# NUC400_v1 register map
File version: 1.0
Registers are 32-bit, read-write, reset 0x0 unless marked. A register's access mark holds for its fields unless they carry their own. Offsets are from the block's base; [hi:lo] are bit positions; {n}, {i} and the like mark numbered series; 'fields as' and 'values as' point back to an identical list.

## EADC — EADC Register Map
Base 0x40044000
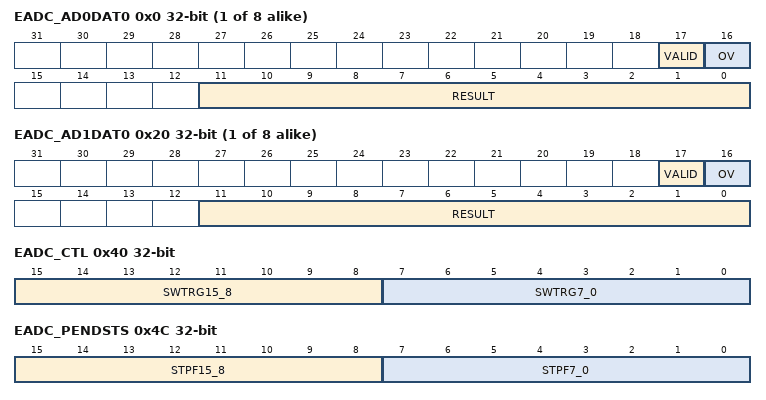
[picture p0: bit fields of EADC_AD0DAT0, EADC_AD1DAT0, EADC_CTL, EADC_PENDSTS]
{0x0+4i} EADC_AD0DAT{i} ro (i=0..7) — A/D Data Register {i} for SAMPLE{i:02}
  [17] VALID — Valid Flag
    0=Data in RESULT (EADC_ADnDATx[11:0]) is not valid; 1=Data in RESULT (EADC_ADnDATx[11:0]) is valid
  [16] OV — Overrun Flag
    0=Data in RESULT (EADC_ADnDATx[11:0]) is recent conversion result; 1=Data in RESULT (EADC_ADnDATx[11:0]) is overwrite
  [11:0] RESULT — A/D Conversion Result. This field contains 12 bits conversion result.
{0x20+4i} EADC_AD1DAT{i} ro (i=0..7) — A/D Data Register {i+8} for SAMPLE{i+10}
  fields as EADC_AD0DAT0
0x40 EADC_CTL — A/D Control Register
  [15:8] SWTRG15_8 — A/D SAMPLE17~SAMPLE10 Software Force To Start ADC Conversion
    0=No effect; 1=Start an ADC conversion when the priority is given to SAMPLE1x
  [7:0] SWTRG7_0 — A/D SAMPLE07~SAMPLE00 Software Force To Start ADC Conversion
    0=No effect; 1=Start an ADC conversion when the priority is given to SAMPLE0x
0x48 EADC_SWTRG wo — A/D SAMPLE Module Software Start Register
0x4C EADC_PENDSTS ro — A/D Start of Conversion Pending Flag Register
  [15:8] STPF15_8 — A/D SAMPLE17~SAMPLE10 Start Of Conversion Pending Flag
    0=There is no pending conversion for SAMPLE1x; 1=SAMPLE1x ADC start of conversion is pending
  [7:0] STPF7_0 — A/D SAMPLE07~SAMPLE00 Start Of Conversion Pending Flag
    0=There is no pending conversion for SAMPLE0x; 1=SAMPLE0x ADC start of conversion is pending
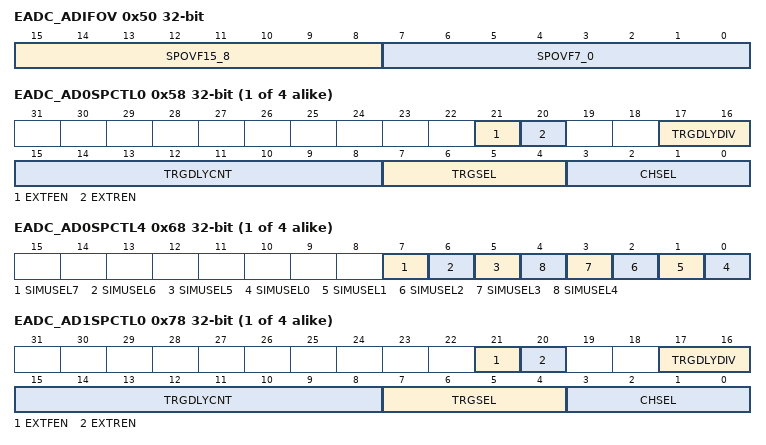
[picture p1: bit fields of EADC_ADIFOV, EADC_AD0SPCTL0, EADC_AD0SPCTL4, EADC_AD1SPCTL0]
0x50 EADC_ADIFOV — A/D ADINT3~0 Interrupt Flag Overrun Register
  [15:8] SPOVF15_8 — A/D SAMPLE17~SAMPLE10 Start Of Conversion Overrun Flag
    0=No SAMPLE1x event overrun; 1=Indicates a new SAMPLE1x event is generated while an old one event is pending
  [7:0] SPOVF7_0 — A/D SAMPLE07~SAMPLE00 Start Of Conversion Overrun Flag
    0=No SAMPLE0x event overrun; 1=Indicates a new SAMPLE0x event is generated while an old one event is pending
0x54 EADC_OVSTS — A/D SAMPLE Module Start of Conversion Overrun Flag Register
{0x58+4i} EADC_AD0SPCTL{i} (i=0..3) — A/D SAMPLE{i:02} Control Register
  [21] EXTFEN — A/D External Pin Falling Edge Trigger Enable Bit
    0=A/D external pin falling edge trigger Disabled; 1=A/D external pin falling edge trigger Enabled
  [20] EXTREN — A/D External Pin Rising Edge Trigger Enable Bit
    0=A/D external pin rising edge trigger Disabled; 1=A/D external pin rising edge trigger Enabled
  [17:16] TRGDLYDIV — A/D SAMPLE MODULE Start Of Conversion Trigger Delay Clock Divider Selection. Trigger delay clock frequency:
    0=ADC_CLK/1; 1=ADC_CLK/2; 2=ADC_CLK/4; 3=ADC_CLK/16
  [15:8] TRGDLYCNT — A/D SAMPLE MODULE Start Of Conversion Trigger Delay Time
  [7:4] TRGSEL — A/D SAMPLE MODULE Start Of Conversion Trigger Source Selection
    0=Disable hardware trigger; 1=External pin (STADC) trigger; 2=ADC ADINT0 interrupt EOC pulse trigger; 3=ADC ADINT1 interrupt EOC pulse trigger; {v}=Timer{v-4} overflow pulse trigger (v=4..7); 8=EPWM0_CH0 trigger; 9=EPWM0_CH2 trigger; 10=EPWM0_CH4 trigger; 11=EPWM1_CH0 trigger; 12=EPWM1_CH2 trigger; 13=EPWM1_CH4 trigger; 14=PWM0_CH0 trigger; 15=PWM0_CH1 trigger
  [3:0] CHSEL — A/D SAMPLE MODULE 0,1 Channel Selection
    {v}=ADCn_CH{v} (v=0..7); 8=VBG. OP1; 9=VTEMP; 10=AVSS; 11=OP0
{0x58+4i} EADC_AD0SPCTL{i} (i=4..7) — A/D SAMPLE{i:02} Control Register
  [7] SIMUSEL7 — A/D SAMPLE07, SAMPLE17 Simultaneous Sampling Mode Selection
    0=SAMPLE07, SAMPLE17 are in single sampling mode, both SAMPLE07 and SAMPLE17's 3 bits of CHSEL define the ADC channels to be converted; 1=SAMPLE07, SAMPLE17 are in simultaneous sampling mode, Only SAMPLE07 can trigger the both ADC conversions of SAMPLE07 and SAMPLE17, SAMPLE17 trigger select TRGSEL is ignored. If SAMPLE07's CHSEL = 1, SAMPLE17's CHSEL = 3, the pair of channels are ADC0_CH1, ADC1_CH3, they will do the ADC conversion at the same time to reach the simulataneous sampling goal
  [6] SIMUSEL6 — A/D SAMPLE06, SAMPLE16 Simultaneous Sampling Mode Selection
    0=SAMPLE06, SAMPLE16 are in single sampling mode, both SAMPLE06 and SAMPLE16's 3 bits of CHSEL define the ADC channels to be converted; 1=SAMPLE06, SAMPLE16 are in simultaneous sampling mode, Only SAMPLE06 can trigger the both ADC conversions of SAMPLE06 and SAMPLE16, SAMPLE16 trigger select TRGSEL is ignored. If SAMPLE06's CHSEL = 1, and SAMPLE16's CHSEL = 3, the pair of channels are ADC0_CH1, ADC1_CH3, they will do the ADC conversion at the same time to reach the simulataneous sampling goal
  [5] SIMUSEL5 — A/D SAMPLE05, SAMPLE15 Simultaneous Sampling Mode Selection
    0=SAMPLE05, SAMPLE15 are in single sampling mode, both SAMPLE05 and SAMPLE15's 3 bits of CHSEL define the ADC channels to be converted; 1=SAMPLE05, SAMPLE15 are in simultaneous sampling mode, Only SAMPLE05 can trigger the both ADC conversions of SAMPLE05 and SAMPLE15, SAMPLE15 trigger select TRGSEL is ignored. if SAMPLE05's CHSEL = 1, and SAMPLE15's CHSEL = 3, the pair of channels are ADC0_CH1, ADC1_CH3, they will do the ADC conversion at the same time to reach the simulataneous sampling goal
  [n] SIMUSEL{n} (n=0..4) — A/D SAMPLE{n:02}, SAMPLE{n+10} Simultaneous Sampling Mode Selection
    0=SAMPLE{n:02}, SAMPLE{n+10} are in single sampling mode, both SAMPLE{n:02} and SAMPLE{n+10}'s 3 bits of CHSEL define the ADC channels to be converted; 1=SAMPLE{n:02}, SAMPLE{n+10} are in simultaneous sampling mode, Only SAMPLE{n:02} can trigger the both ADC conversions of SAMPLE{n:02} and SAMPLE{n+10}, SAMPLE{n+10} trigger select TRGSEL is ignored. If SAMPLE{n:02}'s CHSEL = 1, and SAMPLE{n+10}'s CHSEL = 3, the pair of channels are ADC0_CH1, ADC1_CH3, they will do the ADC conversion at the same time to reach the simulataneous sampling goal
{0x78+4i} EADC_AD1SPCTL{i} (i=0..3) — A/D SAMPLE{i+10} Control Register
  fields as EADC_AD0SPCTL0
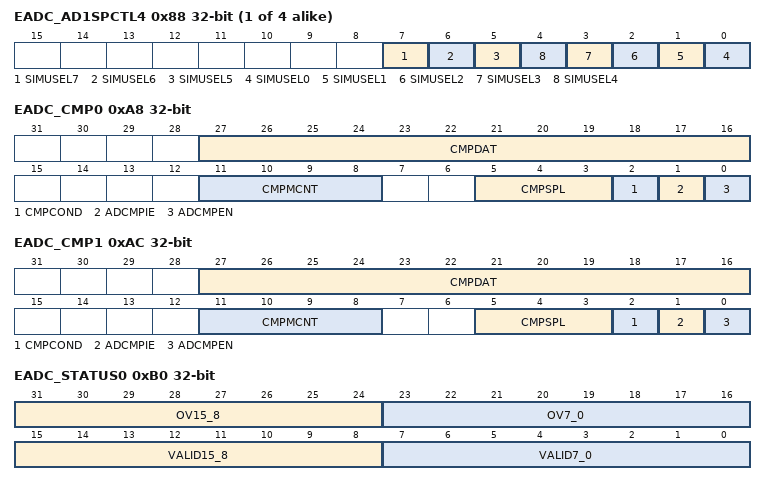
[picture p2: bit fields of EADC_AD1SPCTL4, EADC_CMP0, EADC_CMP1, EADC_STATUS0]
{0x78+4i} EADC_AD1SPCTL{i} (i=4..7) — A/D SAMPLE{i+10} Control Register
  fields as EADC_AD0SPCTL4
0xA4 EADC_SIMUSEL — A/D SAMPLE Module Simultaneous Sampling Mode Select Register
0xA8 EADC_CMP0 — A/D Result Compare Register 0
  [27:16] CMPDAT — Compared Data. The 12 bits data is used to compare with conversion result of specified SAMPLE. Software can use it to monitor the external analog input pin voltage transition without imposing a load on software.
  [11:8] CMPMCNT — Compare Match Count. When the specified A/D SAMPLE MODULE analog conversion result matches the compare condition defined by CMPCOND (EADC_CMPx[2]), the internal match counter will increase 1. When the internal counter reaches the value to CMPMCNT (EADC_CMPx[11:8] + 1, the ADCMPF (EADC_STATUS1 [7:6]) bit will be set.
  [5:3] CMPSPL — Compare SAMPLE MODULE Selection
    {v}=SAMPLE{v:02} conversion result EADC_AD0DAT{v} is selected to be compared (v=0..3); {v}=SAMPLE{v+6} conversion result EADC_AD1DAT{v-4} is selected to be compared (v=4..7)
  [2] CMPCOND — Compare Condition. Note: When the internal counter reaches the value to CMPMCNT (EADC_CMPx[11:8]) + 1, the CMPF bit will be set.
    0=Set the compare condition as that when a 12-bit A/D conversion result is less than the 12-bit CMPDAT (EADC_CMPx[27:16]), the internal match counter will increase one; 1=Set the compare condition as that when a 12-bit A/D conversion result is greater or equal to the 12-bit CMPDAT (EADC_CMPx[27:16]), the internal match counter will increase one
  [1] ADCMPIE — A/D Result Compare Interrupt Enable Bit. If the compare function is enabled and the compare condition matches the setting of CMPCOND (EADC_CMPx[2]) and CMPMCNT (EADC_CMPx[11:8]), ADCMPF (EADC_STATUS1 [7:6]) bit will be asserted, in the meanwhile, if ADCMPIE (EADC_CMPx[1]) is set to 1, a compare interrupt request is generated.
    0=Compare function interrupt Disabled; 1=Compare function interrupt Enabled
  [0] ADCMPEN — A/D Result Compare Enable Bit. Set this bit to 1 to enable compare CMPDAT (EADC_CMPx[27:16]) with specified SAMPLE MODULE conversion result when converted data is loaded into ADDR register.
    0=Compare Disabled; 1=Compare Enabled
0xAC EADC_CMP1 — A/D Result Compare Register 1
  fields as EADC_CMP0
0xB0 EADC_STATUS0 ro — A/D Status Register 0
  [31:24] OV15_8 — ADDR17~ADDR10 Overrun Flag (Read Only). It is a mirror to OV bit in SAMPLE 1 A/D result data register EADC_AD0DAT1x.
  [23:16] OV7_0 — ADDR07~ ADDR00 Overrun Flag (Read Only). It is a mirror to OV bit in SAMPLE0 A/D result data register EADC_AD0DAT0x.
  [15:8] VALID15_8 — ADDR17~ ADDR10 Data Valid Flag (Read Only). It is a mirror of VALID bit in SAMPLE1 A/D result data register EADC_AD0DAT1x.
  [7:0] VALID7_0 — ADDR07~ ADDR00 Data Valid Flag (Read Only). It is a mirror of VALID bit in SAMPLE0 A/D result data register EADC_AD0DAT0x.
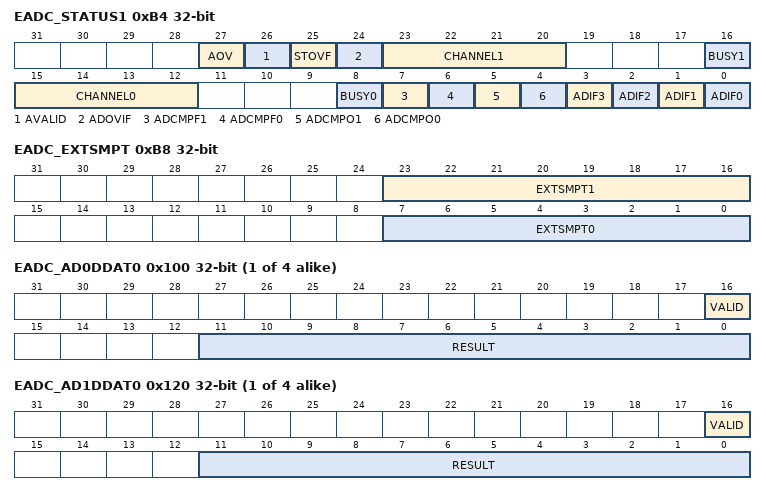
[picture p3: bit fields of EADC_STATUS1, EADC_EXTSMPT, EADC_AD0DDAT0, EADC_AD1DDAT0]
0xB4 EADC_STATUS1 — A/D Status Register 1
  [27] AOV — For All SAMPLE MODULE A/D Result Data Register Overrun Flags Check. Note: This bit will keep 1 when any OVx (EADC_ADnDATx[16]) Flag is equal to 1.
    0=None of SAMPLE MODULE data register overrun flag OVx (EADC_ADnDATx[16]) is set to 1; 1=Any one of SAMPLE MODULE data register overrun flag OVx (EADC_ADnDATx[16]) is set to 1
  [26] AVALID — For All SAMPLE MODULE A/D Result Data Register ADDR Data Valid Flag Check. Note: This bit will keep 1 when any VALIDx (EADC_ADnDATx[17]) Flag is equal to 1.
    0=None of SAMPLE MODULE data register valid flag VALIDx (EADC_ADnDATx[17]) is set to 1; 1=Any one of SAMPLE MODULE data register valid flag VALIDx (EADC_ADnDATx[17]) is set to 1
  [25] STOVF — For All A/D SAMPLE MODULE Start Of Conversion Overrun Flags Check. Note: This bit will keep 1 when any SPOVFx (ADSPOVFR [15:0]) Flag is equal to 1.
    0=None of SAMPLE MODULE event overrun flag SPOVFx (ADSPOVFR [15:0]) is set to 1; 1=Any one of SAMPLE MODULE event overrun flag SPOVFx (ADSPOVFR [15:0]) is set to 1
  [24] ADOVIF — All A/D Interrupt Flag Overrun Bits Check. Note: This bit will keep 1 when any ADFOVx (ADIFOVR [15:0]) Flag is equal to 1.
    0=None of ADINT interrupt flag ADFOVx (ADIFOVR [15:0]) is overwritten to 1; 1=Any one of ADINT interrupt flag ADFOVx (ADIFOVR [15:0]) is overwritten to 1
  [23:20] CHANNEL1 ro — Current Conversion Channel (Read Only)
    {v}=ADC1_CH{v} (v=0..7); 8=OPA1_O
  [16] BUSY1 — Busy/Idle
    0=A/D converter 1 (ADC1) is in idle state; 1=A/D converter 1 (ADC1) is doing conversion
  [15:12] CHANNEL0 ro — Current Conversion Channel (Read Only)
    {v}=ADC0_CH{v} (v=0..3); 4=ADC0_CH4. ADC0_CH5; 6=ADC0_CH6; 7=ADC0_CH7; 8=VBG; 9=VTEMP; 10=AVSS; 11=OPA0_O
  [8] BUSY0 ro — Busy/Idle (Read Only)
    0=A/D converter 0 (ADC0) is in idle state; 1=A/D converter 0 (ADC0) is doing conversion
  [7] ADCMPF1 — ADC Compare 1 Flag. When the specific SAMPLE MODULE A/D conversion result meets setting condition in EADC_CMP1 then this bit is set to 1. Note: This bit is cleared by writing 1 to it.
    0=Conversion result in ADDR does not meet EADC_CMP1 setting; 1=Conversion result in ADDR meets EADC_CMP1 setting
  [6] ADCMPF0 — ADC Compare 0 Flag. When the specific SAMPLE MODULE A/D conversion result meets setting condition in EADC_CMP0 then this bit is set to 1. Note: This bit is cleared by writing 1 to it.
    0=Conversion result in ADDR does not meet EADC_CMP0 setting; 1=Conversion result in ADDR meets EADC_CMP0 setting
  [5] ADCMPO1 — ADC Compare 1 Output Status. The 12 bits compare1 data CMPDAT (EADC_CMP1 [27:16]) is used to compare with conversion result of specified SAMPLE MODULE. Software can use it to monitor the external analog input pin voltage status.
    0=Conversion result in ADDR less than CMPDAT EADC_CMP1 [27:16]) setting; 1=Conversion result in ADDR great than or equal CMPDAT (EADC_CMP1 [27:16]) setting
  [4] ADCMPO0 — ADC Compare 0 Output Status. The 12 bits compare0 data CMPDAT EADC_CMP0 [27:16]) is used to compare with conversion result of specified SAMPLE MODULE. Software can use it to monitor the external analog input pin voltage status.
    0=Conversion result in ADDR less than CMPDAT (EADC_CMP0 [27:16]) setting; 1=Conversion result in ADDR great than or equal CMPDAT (EADC_CMP0 [27:16]) setting
  [3] ADIF3 — A/D ADINT3 Interrupt Flag. Note1: This bit is cleared by writing 1 to it. Note2:This bit indicates whether an A/D conversion of specific SAMPLE MODULE has been completed
    0=No ADINT3 interrupt pulse received; 1=ADINT3 interrupt pulse has been received
  [2] ADIF2 — A/D ADINT2 Interrupt Flag. Note1: This bit is cleared by writing 1 to it. Note2:This bit indicates whether an A/D conversion of specific SAMPLE MODULE has been completed
    0=no ADINT2 interrupt pulse received; 1=ADINT2 interrupt pulse has been received
  [1] ADIF1 — A/D ADINT1 Interrupt Flag. Note1: This bit is cleared by writing 1 to it. Note2:This bit indicates whether an A/D conversion of specific SAMPLE MODULE has been completed
    0=No ADINT1 interrupt pulse received; 1=ADINT1 interrupt pulse has been received
  [0] ADIF0 — A/D ADINT0 Interrupt Flag. Note1: This bit is cleared by writing 1 to it. Note2:This bit indicates whether an A/D conversion of specific SAMPLE MODULE has been completed
    0=No ADINT0 interrupt pulse received; 1=ADINT0 interrupt pulse has been received
0xB8 EADC_EXTSMPT — A/D Timing Control Register
  [23:16] EXTSMPT1 — ADC1 Extend Sampling Time. When A/D converting at high conversion rate, the sampling time of analog input voltage may not enough if input channel loading is heavy, SW can extend A/D sampling time after trigger source is coming to get enough sampling time. The range of start delay time is from 0~255 ADC clock.
  [7:0] EXTSMPT0 — ADC0 Extend Sampling Time. When A/D converting at high conversion rate, the sampling time of analog input voltage may not enough if input channel loading is heavy, SW can extend A/D sampling time after trigger source is coming to get enough sampling time. The range of start delay time is from 0~255 ADC clock.
{0x100+4i} EADC_AD0DDAT{i} ro (i=0..3) — A/D Double Data Register {i} for SAMPLE{i:02}
  [16] VALID — Valid Flag. This bit is set to 1 when corresponding SAMPLE MODULE channel analog input conversion is completed and cleared by hardware after EADC_ADnDATx register is read.
    0=Double buffer data in RESULT (EADC_ADnDATx[11:0]) bits is not valid; 1=Double buffer data in RESULT (EADC_ADnDATx[11:0]) bits is valid
  [11:0] RESULT — A/D Conversion Result. This field contains 12 bits conversion result.
{0x120+4i} EADC_AD1DDAT{i} ro (i=0..3) — A/D Double Data Register {i} for SAMPLE{i+10}
  fields as EADC_AD0DDAT0
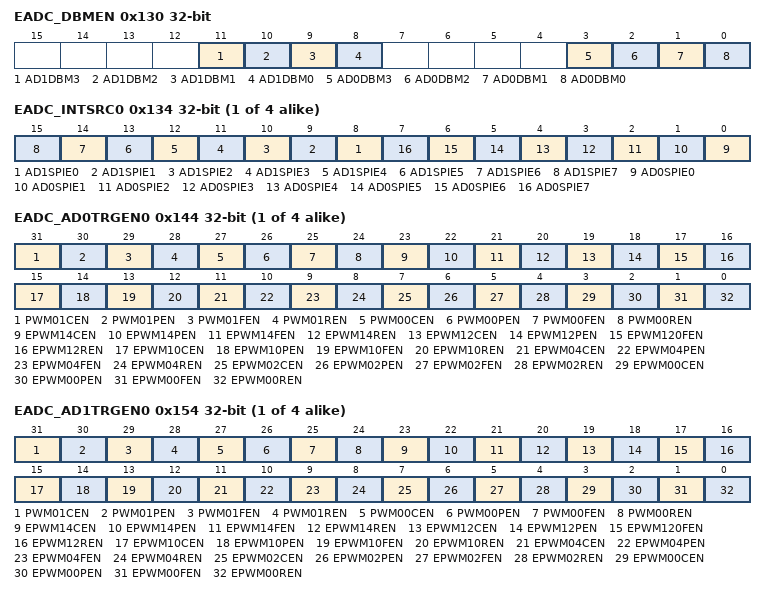
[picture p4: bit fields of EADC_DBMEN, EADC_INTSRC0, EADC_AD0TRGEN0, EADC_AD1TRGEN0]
0x130 EADC_DBMEN — A/D Double Buffer Mode Select
  [11] AD1DBM3 — Double Buffer Mode For SAMPLE13
    0=SAMPLE13 has one sample result register. (default); 1=SAMPLE13 has two sample result registers
  [10] AD1DBM2 — Double Buffer Mode For SAMPLE12
    0=SAMPLE12 has one sample result register. (default).; 1=SAMPLE12 has two sample result registers
  [9] AD1DBM1 — Double Buffer Mode For SAMPLE11
    0=SAMPLE11 has one sample result register. (default); 1=SAMPLE11 has two sample result registers
  [8] AD1DBM0 — Double Buffer Mode For SAMPLE10
    0=SAMPLE10 has one sample result register. (default); 1=SAMPLE10 has two sample result registers
  [3] AD0DBM3 — Double Buffer Mode For SAMPLE03
    0=SAMPLE03 has one sample result register. (default); 1=SAMPLE03 has two sample result registers
  [2] AD0DBM2 — Double Buffer Mode For SAMPLE02
    0=SAMPLE02 has one sample result register. (default).; 1=SAMPLE02 has two sample result registers
  [1] AD0DBM1 — Double Buffer Mode For SAMPLE01
    0=SAMPLE01 has one sample result register. (default); 1=SAMPLE01 has two sample result registers
  [0] AD0DBM0 — Double Buffer Mode For SAMPLE00
    0=SAMPLE00 has one sample result register. (default); 1=SAMPLE00 has two sample result registers
{0x134+4i} EADC_INTSRC{i} (i=0..3) — A/D Interrupt {i} Source Enable Control Register
  [n+8] AD1SPIE{n} (n=0..7) — SAMPLE{n+10} Interrupt Mask Enable Bit
    0=SAMPLE{n+10} interrupt mask Disabled; 1=SAMPLE{n+10} interrupt mask Enabled
  [n] AD0SPIE{n} (n=0..7) — SAMPLE{n:02} Interrupt Mask Enable Bit
    0=SAMPLE{n:02} interrupt mask Disabled; 1=SAMPLE{n:02} interrupt mask Enabled
{0x144+4i} EADC_AD0TRGEN{i} (i=0..3) — A/D Trigger Condition for SAMPLE{i:02}
  [all] fields
    0=Disabled; 1=Enabled
  [31] PWM01CEN — PWM0_CH1 Center Trigger Enable Bit
  [30] PWM01PEN — PWM0_CH1 Period Trigger Enable Bit
  [29] PWM01FEN — PWM0_CH1 Falling Edge Trigger Enable Bit
  [28] PWM01REN — PWM0_CH1 Rising Edge Trigger Enable Bit
  [27] PWM00CEN — PWM0_CH0 Center Trigger Enable Bit
  [26] PWM00PEN — PWM0_CH0 Period Trigger Enable Bit
  [25] PWM00FEN — PWM0_CH0 Falling Edge Trigger Enable Bit
  [24] PWM00REN — PWM0_CH0 Rising Edge Trigger Enable Bit
  [23] EPWM14CEN — EPWM1_CH4 Center Trigger Enable Bit
  [22] EPWM14PEN — EPWM1_CH4 Period Trigger Enable Bit
  [21] EPWM14FEN — EPWM1_CH4 Falling Edge Trigger Enable Bit
  [20] EPWM14REN — EPWM1_CH4 Rising Edge Trigger Enable Bit
  [19] EPWM12CEN — EPWM1_CH2 Center Trigger Enable Bit
  [18] EPWM12PEN — EPWM1_CH2 Period Trigger Enable Bit
  [17] EPWM120FEN — EPWM1_CH2 Falling Edge Trigger Enable Bit
  [16] EPWM12REN — EPWM1_CH2 Rising Edge Trigger Enable Bit
  [15] EPWM10CEN — EPWM1_CH0 Center Trigger Enable Bit
  [14] EPWM10PEN — EPWM1_CH0 Period Trigger Enable Bit
  [13] EPWM10FEN — EPWM1_CH0 Falling Edge Trigger Enable Bit
  [12] EPWM10REN — EPWM1_CH0 Rising Edge Trigger Enable Bit
  [11] EPWM04CEN — EPWM0_CH4 Center Trigger Enable Bit
  [10] EPWM04PEN — EPWM0_CH4 Period Trigger Enable Bit
  [9] EPWM04FEN — EPWM0_CH4 Falling Rdge Trigger Enable Bit
  [8] EPWM04REN — EPWM0_CH4 Rising Edge Trigger Enable Bit
  [7] EPWM02CEN — EPWM0_CH2 Center Trigger Enable Bit
  [6] EPWM02PEN — EPWM0_CH2 Period Trigger Enable Bit
  [5] EPWM02FEN — EPWM0_CH2 Falling Edge Trigger Enable Bit
  [4] EPWM02REN — EPWM0_CH2 Rising Edge Trigger Enable Bit
  [3] EPWM00CEN — EPWM0_CH0 Center Trigger Enable Bit
  [2] EPWM00PEN — EPWM0_CH0 Period Trigger Enable Bit
  [1] EPWM00FEN — EPWM0_CH0 Falling Edge Trigger Enable Bit
  [0] EPWM00REN — EPWM0_CH0 Rising Edge Trigger Enable Bit
{0x154+4i} EADC_AD1TRGEN{i} (i=0..3) — A/D Trigger Condition for SAMPLE{i+10}
  fields as EADC_AD0TRGEN0
